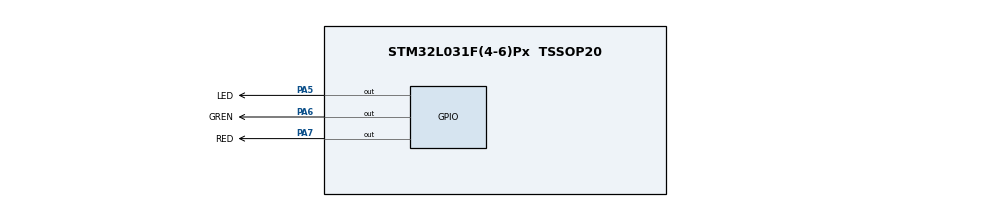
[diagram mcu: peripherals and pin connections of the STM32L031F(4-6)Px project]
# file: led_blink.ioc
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Mcu.Family=STM32L0
Mcu.Name=STM32L031F(4-6)Px
Mcu.Package=TSSOP20
PA13.Mode=Serial_Wire
PA13.Signal=SYS_SWDIO
PA14.Mode=Serial_Wire
PA14.Signal=SYS_SWCLK
PA5.GPIO_Label=LED
PA5.Signal=GPIO_Output
PA6.GPIO_Label=GREN
PA6.Signal=GPIO_Output
PA7.GPIO_Label=RED
PA7.PinState=GPIO_PIN_RESET
PA7.Signal=GPIO_Output
ProjectManager.HeapSize=0x200
ProjectManager.StackSize=0x400
ProjectManager.TargetToolchain=MDK-ARM V5.32
RCC.AHBFreq_Value=2097000
RCC.APB1Freq_Value=2097000
RCC.APB1TimFreq_Value=2097000
RCC.APB2Freq_Value=2097000
RCC.APB2TimFreq_Value=2097000
RCC.HSE_VALUE=8000000
RCC.HSI16_VALUE=16000000
RCC.HSI_VALUE=16000000
RCC.LSE_VALUE=32768
RCC.MSI_VALUE=2097000
RCC.SYSCLKFreq_VALUE=2097000
RCC.VCOOutputFreq_Value=48000000
board=custom

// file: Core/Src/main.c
/* USER CODE BEGIN Header */
/**
  ******************************************************************************
  * @file           : main.c
  * @brief          : Main program body
  ******************************************************************************
  * @attention
  *
  * Copyright (c) 2025 STMicroelectronics.
  * All rights reserved.
  *
  * This software is licensed under terms that can be found in the LICENSE file
  * in the root directory of this software component.
  * If no LICENSE file comes with this software, it is provided AS-IS.
  *
  ******************************************************************************
  */
/* USER CODE END Header */
#include "main.h"
#include "gpio.h"

/* USER CODE BEGIN Includes */
#include "led_effects.h"
/* USER CODE END Includes */

void SystemClock_Config(void);

int main(void)
{

  /* USER CODE BEGIN 1 */
//
  /* USER CODE END 1 */

  /* MCU Configuration--------------------------------------------------------*/

  /* Reset of all peripherals, Initializes the Flash interface and the Systick. */
  LL_APB2_GRP1_EnableClock(LL_APB2_GRP1_PERIPH_SYSCFG);
  LL_APB1_GRP1_EnableClock(LL_APB1_GRP1_PERIPH_PWR);

  /* SysTick_IRQn interrupt configuration */
  NVIC_SetPriority(SysTick_IRQn, 3);

  /* Configure the system clock */
  SystemClock_Config();

  /* Initialize all configured peripherals */
  MX_GPIO_Init();
  /* USER CODE BEGIN 2 */
  LED_Effects_Init();
  /* USER CODE END 2 */

  /* Infinite loop */
  while (1)
  {

    /* USER CODE BEGIN 3 */
    LED_Effects_Process();
    LL_mDelay(1);
  }
  /* USER CODE END 3 */
}

void SystemClock_Config(void)
{
  LL_FLASH_SetLatency(LL_FLASH_LATENCY_0);
  while(LL_FLASH_GetLatency()!= LL_FLASH_LATENCY_0)
  {
  }
  LL_PWR_SetRegulVoltageScaling(LL_PWR_REGU_VOLTAGE_SCALE1);
  while (LL_PWR_IsActiveFlag_VOS() != 0)
  {
  }
  LL_RCC_MSI_Enable();

   /* Wait till MSI is ready */
  while(LL_RCC_MSI_IsReady() != 1)
  {

  }
  LL_RCC_MSI_SetRange(LL_RCC_MSIRANGE_5);
  LL_RCC_MSI_SetCalibTrimming(0);
  LL_RCC_SetAHBPrescaler(LL_RCC_SYSCLK_DIV_1);
  LL_RCC_SetAPB1Prescaler(LL_RCC_APB1_DIV_1);
  LL_RCC_SetAPB2Prescaler(LL_RCC_APB2_DIV_1);
  LL_RCC_SetSysClkSource(LL_RCC_SYS_CLKSOURCE_MSI);

   /* Wait till System clock is ready */
  while(LL_RCC_GetSysClkSource() != LL_RCC_SYS_CLKSOURCE_STATUS_MSI)
  {

  }

  LL_Init1msTick(2097000);

  LL_SetSystemCoreClock(2097000);
}

void Error_Handler(void)
{
  __disable_irq();
  while (1)
  {
  }
}
